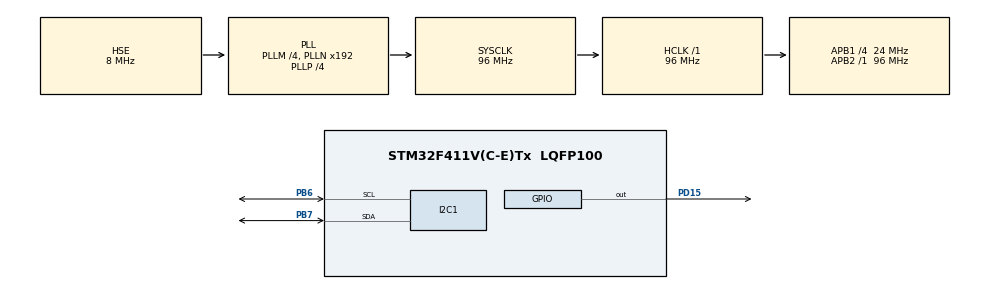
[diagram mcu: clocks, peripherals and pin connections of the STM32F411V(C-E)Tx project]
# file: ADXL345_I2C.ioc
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I2C1.I2C_Mode=I2C_Fast
Mcu.Family=STM32F4
Mcu.Name=STM32F411V(C-E)Tx
Mcu.Package=LQFP100
NVIC.I2C1_EV_IRQn=true\:0\:0\:false\:false\:true\:true\:true\:true
NVIC.PriorityGroup=NVIC_PRIORITYGROUP_0
PA13.Mode=Serial_Wire
PA13.Signal=SYS_JTMS-SWDIO
PA14.Mode=Serial_Wire
PA14.Signal=SYS_JTCK-SWCLK
PB6.Mode=I2C
PB6.Signal=I2C1_SCL
PB7.Mode=I2C
PB7.Signal=I2C1_SDA
PD15.Signal=GPIO_Output
PH0\ -\ OSC_IN.Mode=HSE-External-Oscillator
PH0\ -\ OSC_IN.Signal=RCC_OSC_IN
PH1\ -\ OSC_OUT.Mode=HSE-External-Oscillator
PH1\ -\ OSC_OUT.Signal=RCC_OSC_OUT
ProjectManager.HeapSize=0x200
ProjectManager.StackSize=0x400
ProjectManager.TargetToolchain=STM32CubeIDE
RCC.48MHZClocksFreq_Value=48000000
RCC.AHBFreq_Value=96000000
RCC.APB1CLKDivider=RCC_HCLK_DIV4
RCC.APB1Freq_Value=24000000
RCC.APB1TimFreq_Value=48000000
RCC.APB2Freq_Value=96000000
RCC.APB2TimFreq_Value=96000000
RCC.CortexFreq_Value=96000000
RCC.HCLKFreq_Value=96000000
RCC.HSE_VALUE=8000000
RCC.HSI_VALUE=16000000
RCC.PLLI2SM=5
RCC.PLLI2SN=200
RCC.PLLM=4
RCC.PLLP=RCC_PLLP_DIV4
RCC.PLLQ=8
RCC.PLLSourceVirtual=RCC_PLLSOURCE_HSE
RCC.SYSCLKFreq_VALUE=96000000
RCC.SYSCLKSource=RCC_SYSCLKSOURCE_PLLCLK
RCC.VCOOutputFreq_Value=384000000
board=STM32F411E-DISCO

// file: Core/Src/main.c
#include "main.h"
#include "ADXL345.h"
/* USER CODE BEGIN Includes */

I2C_HandleTypeDef hi2c1;

/* USER CODE BEGIN PV */

float x_acc,y_acc, z_acc;

/* USER CODE END PV */

void SystemClock_Config(void);
static void MX_GPIO_Init(void);
static void MX_I2C1_Init(void);

int main(void)
{

  HAL_Init();

  /* Configure the system clock */
  SystemClock_Config();

  /* Initialize all configured peripherals */
  MX_GPIO_Init();
  MX_I2C1_Init();
  /* USER CODE BEGIN 2 */

  Scan_I2C_Address(); // address bulmak için
  ADX345_Init(RANGE_16G);

  /* USER CODE END 2 */

  while (1)
  {
    /* USER CODE BEGIN 3 */

	  x_acc = ADXL345_Get_Value_X();
  }
  /* USER CODE END 3 */
}

void SystemClock_Config(void)
{
  RCC_OscInitTypeDef RCC_OscInitStruct = {0};
  RCC_ClkInitTypeDef RCC_ClkInitStruct = {0};

  /** Configure the main internal regulator output voltage
  */
  __HAL_RCC_PWR_CLK_ENABLE();
  __HAL_PWR_VOLTAGESCALING_CONFIG(PWR_REGULATOR_VOLTAGE_SCALE1);

  /** Initializes the RCC Oscillators according to the specified parameters
  * in the RCC_OscInitTypeDef structure.
  */
  RCC_OscInitStruct.OscillatorType = RCC_OSCILLATORTYPE_HSE;
  RCC_OscInitStruct.HSEState = RCC_HSE_ON;
  RCC_OscInitStruct.PLL.PLLState = RCC_PLL_ON;
  RCC_OscInitStruct.PLL.PLLSource = RCC_PLLSOURCE_HSE;
  RCC_OscInitStruct.PLL.PLLM = 4;
  RCC_OscInitStruct.PLL.PLLN = 192;
  RCC_OscInitStruct.PLL.PLLP = RCC_PLLP_DIV4;
  RCC_OscInitStruct.PLL.PLLQ = 8;
  if (HAL_RCC_OscConfig(&RCC_OscInitStruct) != HAL_OK)
  {
    Error_Handler();
  }

  /** Initializes the CPU, AHB and APB buses clocks
  */
  RCC_ClkInitStruct.ClockType = RCC_CLOCKTYPE_HCLK|RCC_CLOCKTYPE_SYSCLK
                              |RCC_CLOCKTYPE_PCLK1|RCC_CLOCKTYPE_PCLK2;
  RCC_ClkInitStruct.SYSCLKSource = RCC_SYSCLKSOURCE_PLLCLK;
  RCC_ClkInitStruct.AHBCLKDivider = RCC_SYSCLK_DIV1;
  RCC_ClkInitStruct.APB1CLKDivider = RCC_HCLK_DIV4;
  RCC_ClkInitStruct.APB2CLKDivider = RCC_HCLK_DIV1;

  if (HAL_RCC_ClockConfig(&RCC_ClkInitStruct, FLASH_LATENCY_3) != HAL_OK)
  {
    Error_Handler();
  }
}

static void MX_I2C1_Init(void)
{

  hi2c1.Instance = I2C1;
  hi2c1.Init.ClockSpeed = 400000;
  hi2c1.Init.DutyCycle = I2C_DUTYCYCLE_2;
  hi2c1.Init.OwnAddress1 = 0;
  hi2c1.Init.AddressingMode = I2C_ADDRESSINGMODE_7BIT;
  hi2c1.Init.DualAddressMode = I2C_DUALADDRESS_DISABLE;
  hi2c1.Init.OwnAddress2 = 0;
  hi2c1.Init.GeneralCallMode = I2C_GENERALCALL_DISABLE;
  hi2c1.Init.NoStretchMode = I2C_NOSTRETCH_DISABLE;
  if (HAL_I2C_Init(&hi2c1) != HAL_OK)
  {
    Error_Handler();
  }

}

static void MX_GPIO_Init(void)
{
  GPIO_InitTypeDef GPIO_InitStruct = {0};

  /* GPIO Ports Clock Enable */
  __HAL_RCC_GPIOH_CLK_ENABLE();
  __HAL_RCC_GPIOD_CLK_ENABLE();
  __HAL_RCC_GPIOA_CLK_ENABLE();
  __HAL_RCC_GPIOB_CLK_ENABLE();

  /*Configure GPIO pin Output Level */
  HAL_GPIO_WritePin(GPIOD, GPIO_PIN_15, GPIO_PIN_RESET);

  /*Configure GPIO pin : PD15 */
  GPIO_InitStruct.Pin = GPIO_PIN_15;
  GPIO_InitStruct.Mode = GPIO_MODE_OUTPUT_PP;
  GPIO_InitStruct.Pull = GPIO_NOPULL;
  GPIO_InitStruct.Speed = GPIO_SPEED_FREQ_LOW;
  HAL_GPIO_Init(GPIOD, &GPIO_InitStruct);

}

void Error_Handler(void)
{
  __disable_irq();
  while (1)
  {
  }
}
